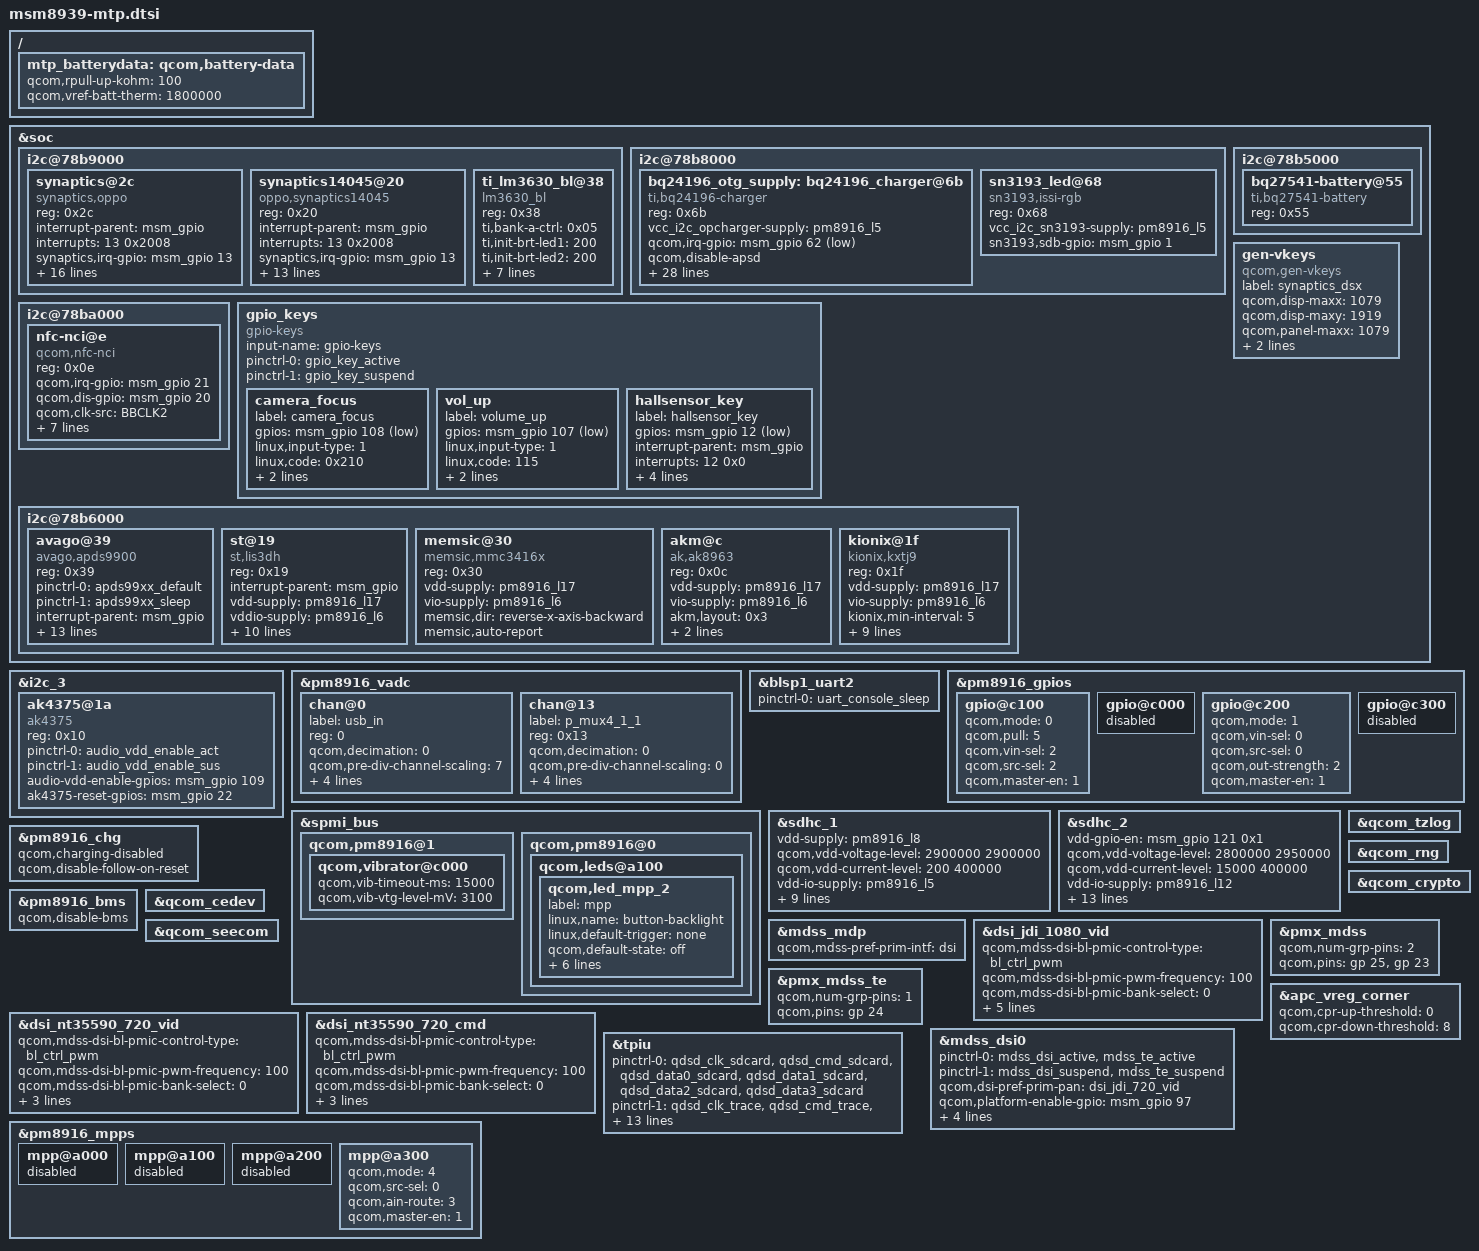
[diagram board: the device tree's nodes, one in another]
/* Copyright (c) 2014-2015, The Linux Foundation. All rights reserved.
 *
 * This program is free software; you can redistribute it and/or modify
 * it under the terms of the GNU General Public License version 2 and
 * only version 2 as published by the Free Software Foundation.
 *
 * This program is distributed in the hope that it will be useful,
 * but WITHOUT ANY WARRANTY; without even the implied warranty of
 * MERCHANTABILITY or FITNESS FOR A PARTICULAR PURPOSE.  See the
 * GNU General Public License for more details.
 */

#include "msm8939-pinctrl.dtsi"
#include "msm8939-camera-sensor-mtp.dtsi"

&soc {
	i2c@78b9000 { /* BLSP1 QUP5 */
	
		synaptics@2c {/*chenggang.li add for TP */
			compatible = "synaptics,oppo";
			reg = <0x2c>;
			interrupt-parent = <&msm_gpio>;
			interrupts = <13 0x2008>;
			synaptics,irq-gpio = <&msm_gpio 13 0x2008>;
			synaptics,id1-gpio = <&msm_gpio 51 0x00>;
			/*synaptics,id2-gpio = <&msm_gpio 66 0x00>;
			synaptics,id3-gpio = <&msm_gpio 119 0x00>;*/
			pinctrl-names = "default";
			pinctrl-0 = <&ts_id1_default   &ts_int_active>;
			synaptics,reset-gpio = <&msm_gpio 25 0x00>;
			synaptics,enable1v814045-gpio = <&msm_gpio 23 0x00>;
			vdd_2v8-supply = <&pm8916_l11>;
			vcc_i2c_1v8-supply = <&pm8916_l16>;
			synaptics,max-num-support = <10>;
			synaptics,max-x-point = <10>;
			synaptics,max-y-point = <1745>;
			synaptics,button-map= <200 200 1380>;//width-height-y.position
			synaptics,tx-rx-num = <28 18>;
			synaptics,display-coords = <720 1280>;
			synaptics,i2c-pull-up;
			synaptics,power-down;
			synaptics,disable-gpios;
			//synaptics,display-coords = <0 0 1079 1919>;
			synaptics,panel-coords = <0 0 1079 2084>;
		};
		
		synaptics14045@20 {/*tong.han add for TP */
			compatible = "oppo,synaptics14045";
			reg = <0x20>;
			interrupt-parent = <&msm_gpio>;
			interrupts = <13 0x2008>;
			synaptics,irq-gpio = <&msm_gpio 13 0x2008>;
			synaptics,id1-gpio = <&msm_gpio 51 0x00>;
			/*synaptics,id2-gpio = <&msm_gpio 66 0x00>;
			synaptics,id3-gpio = <&msm_gpio 119 0x00>;*/
			pinctrl-names = "default";
			pinctrl-0 = <&ts_id1_default   &ts_int_active>;
			//synaptics,reset-gpio = <&pm8916_gpios 2 0x00>;
			synaptics,max-num-support = <10>;
			synaptics,max-x-point = <10>;
			synaptics,max-y-point = <1745>;
			synaptics,button-map= <160 226 1400>;//width-height-y.position
			synaptics,tx-rx-num = <28 18>;
			synaptics,display-coords = <720 1280>;
			vdd_2v8-supply = <&pm8916_l11>;
			vcc_i2c_1v8-supply = <&pm8916_l16>;
			synaptics,i2c-pull-up;
			synaptics,power-down;
			synaptics,disable-gpios;
		};
		/* OPPO 2014-09-08 Xiaori.Yuan add begin for backlight lm3630 */
		ti_lm3630_bl@38 {
			compatible = "lm3630_bl";
			reg = <0x38>;
			ti,bank-a-ctrl = <0x05>;
			ti,init-brt-led1 = <200>;
			ti,init-brt-led2 = <200>;
			ti,max-brt-led1 = <255>;
			ti,max-brt-led2 = <255>;
			ti,pwm-active = <0>;
			ti,pwm-ctrl = <0>;
			ti,pwm-period = <255>;
			bl_i2c_1v8_enable_gpio = <&msm_gpio 23 0x00>;
			ti,bl-enable-gpio = <&msm_gpio 69 0>;
		};
		/* OPPO 2014-09-08 Xiaori.Yuan add end */
	};
	i2c@78b8000 { /* BLSP1 QUP4 =i2c4*/
		//Add bq24196_otg_supply for vbus_otg-supply by qiujianfeng
		bq24196_otg_supply: bq24196_charger@6b {
			status = "okay";
			compatible = "ti,bq24196-charger";
			reg = <0x6b>;

			vcc_i2c_opcharger-supply = <&pm8916_l5>;			/*Power source required to pull up i2c bus*/
			qcom,irq-gpio = <&msm_gpio 62 0x01>;					/*gpio STAT pin connects to.*/
			//qcom,fast_charger-gpio = <&msm_gpio 23 0x01>;			/*gpio fast_charger pin connects to.*/
			//qcom,usbphy_on-gpio = <&msm_gpio 38 0x01>;			/*gpio fast_charger pin connects to.*/
			//qcom,chg-valid-gpio= <&pm8941_gpios 0x02 0x01>;	/* */
			//qcom,charging-disabled;											/*This can then be overriden writing the the module parameter "charging_disabled"*/
			//qcom,chg-autonomous-mode;											/*it indicates that the charger is configured for autonomous operation*/
			qcom,disable-apsd;										/*APSD */
			qcom,bms-psy-name = "bms";									/*The main BMS device name */
			//qcom,iterm-disabled;
			qcom,charger-inhibit-disabled;							/* Charge Inhibit  */
			qcom,chg-vadc = <&pm8916_vadc>;							/* Corresponding VADC device's phandle.*/
			qcom,chg-adc_tm = <&pm8916_adc_tm>;						/* set recurring measurements and receive notification for batt_therm. */

			qcom,iterm-ma = <150>;									/*Charge termination current*/
			qcom,recharge-mv = <100>;									/* The minimum voltage drop for recharger*/
			qcom,fast-charger-project-sign= <0>;						/* fastcharger project sign*/	
			qcom,fastchg-current-max-ma = <1500>;						/*Maximum fast charging current.*/
			qcom,input-current-max-ma = <1500>;						/*Maximum input current.*/
			qcom,float-voltage-mv = <4320>;							/* from constant current charging to constant voltage chargeing for voltage threshold*/

			qcom,hot_bat_decidegc = <550>;							/* hot battery temperature in decidegC = 55*/
			qcom,temp_hot_vfloat_mv = <4100>;							/* hot battery temperature cutoff voltage =4.1V (45~55)*/
			qcom,temp_hot_fastchg_current_ma = <720>;					/* hot battery temperature fast current   =0.75A (45~55)*/

			qcom,warm_bat_decidegc = <450>;							/* Warm battery temperature in decidegC= 45*/
			qcom,temp_warm_vfloat_mv = <4320>;						/* warn battery temperature cutoff voltage =4.1V (5~45)*/
			qcom,temp_warm_fastchg_current_ma = <1500>;				/* warn battery temperature fast current   =0.75A (5~45)*/

			qcom,pre_normal_bat_decidegc = <200>;						/* pre_cool battery temperature in decidegC= 5*/	
			qcom,temp_pre_normal_vfloat_mv = <4320>;						/* warn battery temperature cutoff voltage =4.1V (5~45)*/
			qcom,temp_pre_normal_fastchg_current_ma = <1200>;			/* warn battery temperature fast current   =0.75A (5~45)*/

			qcom,pre_cool_bat_decidegc = <100>;						/* pre_cool battery temperature in decidegC= 5*/	
			qcom,temp_pre_cool_vfloat_mv = <4200>;					/* pre_cool battery temperature cutoff voltage =4.2V (0~5)*/
			qcom,temp_pre_cool_fastchg_current_ma = <500>;			/* pre_cool battery temperature fast current   =0.75A (0~5)*/

			qcom,cool_bat_decidegc = <0>;								/* cool battery temperature in decidegC= 0*/
			qcom,temp_cool_vfloat_mv = <4000>;						/* cool battery temperature cutoff voltage =4.0V (-10~0) */
			qcom,temp_cool_fastchg_current_ma = <300>;				/* cool battery temperature fast current   =0.25A(-10~0)*/

			qcom,cold_bat_decidegc = <100>;							/* cold battery temperature in decidegC= -10*/
			qcom,bat_present_decidegc = <200>;						/* battery decidegc temperature in decidegC= -20*/
			//qcom,non_standard_vfloat_mv = <4000>;
			//qcom,non_standard_fastchg_current_ma = <512>;

			//Modify regulator name by qiujianfeng
			regulator-name = "bq24196_otg_vreg";
		}; 		
                //#ifdef VENDOR_EDIT Jianfeng.Qiu@BSP.Driver, 2014-09-11, Add for breath led
                sn3193_led@68 {
                        status = "okay";
                        compatible = "sn3193,issi-rgb";
                        reg = <0x68>;
                        vcc_i2c_sn3193-supply = <&pm8916_l5>;			/*Power source required to pull up i2c bus*/
                        sn3193,sdb-gpio = <&msm_gpio 1 0x00>;
                };
                //#endif
	};
	i2c@78b5000 { /* BLSP1 QUP1 */
		bq27541-battery@55 {
			status = "okay";
			compatible = "ti,bq27541-battery";
			reg = <0x55>;

		};
	};
	gen-vkeys {
		compatible = "qcom,gen-vkeys";
		label = "synaptics_dsx";
		qcom,disp-maxx = <1079>;
		qcom,disp-maxy = <1919>;
		qcom,panel-maxx = <1079>;
		qcom,panel-maxy = <2084>;
		qcom,key-codes = <158 139 172 217>;
	};

	i2c@78ba000 { /* BLSP1 QUP6 */
		nfc-nci@e {
			compatible = "qcom,nfc-nci";
			reg = <0x0e>;
			qcom,irq-gpio = <&msm_gpio 21 0x00>;
			qcom,dis-gpio = <&msm_gpio 20 0x00>;
			qcom,clk-src = "BBCLK2";
			interrupt-parent = <&msm_gpio>;
			interrupts = <21 0>;
			interrupt-names = "nfc_irq";
			pinctrl-names = "nfc_active","nfc_suspend";
			pinctrl-0 = <&nfc_int_active &nfc_disable_active>;
			pinctrl-1 = <&nfc_int_suspend &nfc_disable_suspend>;
			qcom,clk-gpio = <&pm8916_gpios 2 0>;
			clocks = <&clock_rpm clk_bb_clk2_pin>;
			clock-names = "ref_clk";
		};
	};
	gpio_keys {
		compatible = "gpio-keys";
		input-name = "gpio-keys";
		pinctrl-names = "tlmm_gpio_key_active","tlmm_gpio_key_suspend";
		pinctrl-0 = <&gpio_key_active>;
		pinctrl-1 = <&gpio_key_suspend>;

		camera_focus {
			label = "camera_focus";
			gpios = <&msm_gpio 108 0x1>;
			linux,input-type = <1>;
			linux,code = <0x210>;
			gpio-key,wakeup;
			debounce-interval = <15>;
		};

		/*
		//#ifdef VENDOR_EDIT  
   		//deleted by zhengzhiyong@Multimedia.group (conflict with AUDIO_LDO_EN ) 2014-9-11  
		camera_snapshot {
			label = "camera_snapshot";
			gpios = <&msm_gpio 109 0x1>;
			linux,input-type = <1>;
			linux,code = <0x2fe>;
			gpio-key,wakeup;
			debounce-interval = <15>;
		};
		//#endif
		*/
		
		vol_up {
			label = "volume_up";
			gpios = <&msm_gpio 107 0x1>;
			linux,input-type = <1>;
			linux,code = <115>;
			gpio-key,wakeup;
			debounce-interval = <15>;
		};

		/* LiuPing@Phone.BSP.Sensor, 2014/11/07, add for hall */
		hallsensor_key {
			label = "hallsensor_key";
			gpios = <&msm_gpio 12 1>;
			interrupt-parent = <&msm_gpio>;
			interrupts = <12 0x0>;
			linux,input-type = <5>;
			linux,code = <0>;
			gpio-key,wakeup;
			debounce-interval = <150>;
		};

	};

	i2c@78b6000 { /* BLSP1 QUP2 */

	       /* LiuPing@Phone.BSP.Sensor, 2014/12/30, remove unused sensor. */
	       /* Gyroscope and accelerometer sensor combo */
	       /*
		mpu6050@68 { 
			compatible = "invn,mpu6050";
			reg = <0x68>;
			pinctrl-names = "mpu_default","mpu_sleep";
			pinctrl-0 = <&mpu6050_default>;
			pinctrl-1 = <&mpu6050_sleep>;
			interrupt-parent = <&msm_gpio>;
			interrupts = <115 0x2>;
			vdd-supply = <&pm8916_l17>;
			vlogic-supply = <&pm8916_l16>;
			vi2c-supply = <&pm8916_l6>;
			invn,gpio-int = <&msm_gpio 115 0x2>;
			invn,place = "Portrait Down Back Side";
		};*/

		avago@39 { /* Ambient light and proximity sensor */
			compatible = "avago,apds9900";
			reg = <0x39>;
			pinctrl-names = "default","sleep";
			pinctrl-0 = <&apds99xx_default>;
			pinctrl-1 = <&apds99xx_sleep>;
			interrupt-parent = <&msm_gpio>;
			interrupts = <9 0x2002>;
			vdd-supply = <&pm8916_l17>;
			vio-supply = <&pm8916_l6>;
			avago,irq-gpio = <&msm_gpio 9 0x2002>;
			avago,ps-threshold = <1023>;
			avago,ps-hysteresis-threshold = <1023>;
			avago,ps-pulse = <8>;
			avago,ps-pgain = <0>;
			avago,als-B = <223>;
			avago,als-C = <70>;
			avago,als-D = <142>;
			avago,als-gain = <80>;   // the true: lux = lux*als_gain/100.
			avago,ga-value = <48>;
		};

		/* LiuPing@Phone.BSP.Sensor, 2014/09/02, add for gsensor:lis3dh */
		st@19 { /* Accelerometer sensor */
			compatible = "st,lis3dh";
			reg = <0x19>;
			interrupt-parent = <&msm_gpio>;
			vdd-supply = <&pm8916_l17>;
			vddio-supply = <&pm8916_l6>;
			st,min-interval = <5>;
			st,init-interval = <200>;
			st,axis-map-x = <1>;
			st,axis-map-y = <0>;
			st,axis-map-z = <2>;
			st,g-range = <2>;
			st,gpio-int1 = <&msm_gpio 34 0x2002>;
			st,negate-x;
			st,negate-y;			
			st,negate-z;
		};			

		/* LiuPing@Phone.BSP.Sensor, 2014/09/04, add for msensor:mmc3416x */
		memsic@30 { /* Magnetic field sensor */
		compatible = "memsic,mmc3416x";
		reg = <0x30>;
		vdd-supply = <&pm8916_l17>;
		vio-supply = <&pm8916_l6>;
		memsic,dir = "reverse-x-axis-backward";
		memsic,auto-report;
		};		

		/* LiuPing@Phone.BSP.Sensor, 2014/10/30, add for msensor:akm8963 */
		akm@c {
			compatible = "ak,ak8963";
			reg = <0x0c>;
			/* pinctrl-names = "ak8963_default", "ak8963_sleep";
			pinctrl-0 = <&ak8963_default>;
			pinctrl-1 = <&ak8963_sleep>;
			interrupt-parent = <&msm_gpio>;
			interrupts = <69 0x2>; */
			vdd-supply = <&pm8916_l17>;
			vio-supply = <&pm8916_l6>;
			akm,layout = <0x3>;
			akm,gpio_rstn = <&msm_gpio 106 0x0>;
			akm,auto-report;
		};
		/* LiuPing@Phone.BSP.Sensor, 2014/10/30, add for gsensor:kx023 */
		kionix@1f { 
			compatible = "kionix,kxtj9";
			reg = <0x1f>;
			//interrupt-parent = <&msm_gpio>;
			//interrupts = <34 0x2>;
			vdd-supply = <&pm8916_l17>;
			vio-supply = <&pm8916_l6>;
			kionix,min-interval = <5>;
			kionix,init-interval = <200>;
			kionix,axis-map-x = <1>;
			kionix,axis-map-y = <0>;
			kionix,axis-map-z = <2>;
			kionix,g-range = <2>;
			kionix,negate-x;
			kionix,negate-y;
			kionix,negate-z;
			kionix,res-12bit; 
		};

	};

};
/*OPPO 2014-08-20 zhzhyon Add for ak4375*/
&i2c_3 {
		  ak4375@1a {
			compatible = "ak4375";
			reg = <0x10>;
			pinctrl-names = "cdc_audio_enable_act",
				  "cdc_audio_enable_sus";
			pinctrl-0 = <&audio_vdd_enable_act>;
		  pinctrl-1 = <&audio_vdd_enable_sus>;
			audio-vdd-enable-gpios = <&msm_gpio 109 0x00>;	
			/*OPPO 2014-09-23 zhzhyon Add for ak4375 resource*/
			ak4375-reset-gpios = <&msm_gpio 22 0x00>;
			/*OPPO 2014-09-23 zhzhyon Add end*/
		};		
	};
/*OPPO 2014-08-20 zhzhyon Add end*/


/*dengnw  add for  adc 2014-07-22 start*/
&pm8916_vadc {
	chan@0 {
		label = "usb_in";
		reg = <0>;
		qcom,decimation = <0>;
		qcom,pre-div-channel-scaling = <7>;
		qcom,calibration-type = "absolute";
		qcom,scale-function = <0>;
		qcom,hw-settle-time = <0>;
		qcom,fast-avg-setup = <0>;
	};
	chan@13 {
		label = "p_mux4_1_1";
		reg = <0x13>;
		qcom,decimation = <0>;
		qcom,pre-div-channel-scaling = <0>;
		qcom,calibration-type = "absolute";
		qcom,scale-function = <0>;
		qcom,hw-settle-time = <2>;
		qcom,fast-avg-setup = <0>;
	};
};
/*dengnw  add for  adc 2014-07-22 end*/
&blsp1_uart2 {
	status = "ok";
	pinctrl-names = "default";
	pinctrl-0 = <&uart_console_sleep>;
};

&pm8916_gpios {
	gpio@c100 { /* GPIO 2 */
		/* NFC_CLK_REQ */
		qcom,mode = <0>; /* QPNP_PIN_MODE_DIG_IN */
		qcom,pull = <5>; /* QPNP_PIN_PULL_NO */
		qcom,vin-sel = <2>; /* QPNP_PIN_VIN2 */
		qcom,src-sel = <2>; /* QPNP_PIN_SEL_FUNC_1 */
		qcom,master-en = <1>;
	};
};
&spmi_bus {
	qcom,pm8916@1 {
		qcom,vibrator@c000 {
			status = "okay";
			qcom,vib-timeout-ms = <15000>;
			qcom,vib-vtg-level-mV = <3100>;
		};
	};

	qcom,pm8916@0 {
		qcom,leds@a100 {
			status = "okay";
			qcom,led_mpp_2 {
				label = "mpp";
				linux,name = "button-backlight";
				linux,default-trigger = "none";
				qcom,default-state = "off";
				qcom,max-current = <40>;
				qcom,current-setting = <5>;
				qcom,id = <6>;
				qcom,mode = "manual";
				qcom,source-sel = <1>;
				qcom,mode-ctrl = <0x60>;
			};
		};
	};
};

&sdhc_1 {
	vdd-supply = <&pm8916_l8>;
	qcom,vdd-voltage-level = <2900000 2900000>;
	qcom,vdd-current-level = <200 400000>;

	vdd-io-supply = <&pm8916_l5>;
	qcom,vdd-io-always-on;
	qcom,vdd-io-lpm-sup;
	qcom,vdd-io-voltage-level = <1800000 1800000>;
	qcom,vdd-io-current-level = <200 60000>;

	pinctrl-names = "active", "sleep";
	pinctrl-0 = <&sdc1_clk_on &sdc1_cmd_on &sdc1_data_on>;
	pinctrl-1 = <&sdc1_clk_off &sdc1_cmd_off &sdc1_data_off>;

	qcom,nonremovable;

	status = "ok";
};

&sdhc_2 {
//#ifndef VENDOR_EDIT //Jianfeng.Qiu@BSP.Driver, 2014-09-13, Modify for tf card vdd supply change
	//vdd-supply = <&pm8916_l11>;
//#else /* VENDOR_EDIT */
    vdd-gpio-en = <&msm_gpio 121 0x1>;
//#endif /* VENDOR_EDIT */
	qcom,vdd-voltage-level = <2800000 2950000>;
	qcom,vdd-current-level = <15000 400000>;

	vdd-io-supply = <&pm8916_l12>;
	qcom,vdd-io-voltage-level = <1800000 2950000>;
	qcom,vdd-io-current-level = <200 50000>;

	//#ifndef VENDOR_EDIT //Jianfeng.Qiu@BSP.Drv, 2014-8-13, Modify for delete card hotplug
	//pinctrl-names = "active", "sleep";
	//pinctrl-0 = <&sdc2_clk_on &sdc2_cmd_on &sdc2_data_on &sdc2_cd_on>;
	//pinctrl-1 = <&sdc2_clk_off &sdc2_cmd_off &sdc2_data_off &sdc2_cd_off>;
	//#else
	pinctrl-names = "default", "active", "sleep";
	pinctrl-0 = <&sdc2_cd_on &sim1_cd_on &sim2_cd_on>;
	pinctrl-1 = <&sdc2_clk_on &sdc2_cmd_on &sdc2_data_on &sdc2_cd_on>;
	pinctrl-2 = <&sdc2_clk_off &sdc2_cmd_off &sdc2_data_off &sdc2_cd_off>;
	//#endif
	
	#address-cells = <0>;
	interrupt-parent = <&sdhc_2>;
	
	//#ifndef VENDOR_EDIT //Jianfeng.Qiu@BSP.Drv, 2014-8-13, Modify for delete card hotplug
	interrupts = <0 1 2>;
	#interrupt-cells = <1>;
	interrupt-map-mask = <0xffffffff>;
	interrupt-map = <0 &intc 0 125 0
			1 &intc 0 221 0
			2 &msm_gpio 38 0>;
	interrupt-names = "hc_irq", "pwr_irq", "status_irq";
	//#ifdef VENDOR_EDIT //yixue.ge modify for 14045 tcard hotplug
	//cd-gpios = <&msm_gpio 38 0x1>;
	//#else
	cd-gpios = <&msm_gpio 38 0x0>;
	//#endif
	//#else
	/*	
	interrupts = <0 1>;
	#interrupt-cells = <1>;
	interrupt-map-mask = <0xffffffff>;
	interrupt-map = <0 &intc 0 125 0
			1 &intc 0 221 0>;
	interrupt-names = "hc_irq", "pwr_irq";
	*/
	//#endif
	status = "ok";
};

&pm8916_chg {
	status = "ok";
	qcom,charging-disabled;
	/*dengnw@bsp.drv  add for  adc 2014-07-22 end*/
	qcom,disable-follow-on-reset;
};

/ {
	mtp_batterydata: qcom,battery-data {
		qcom,rpull-up-kohm = <100>;
		qcom,vref-batt-therm = <1800000>;

		#include "batterydata-palladium.dtsi"
	};
};

&pm8916_bms {
	status = "ok";
	/*dengnw@bsp.drv  add for  adc 2014-07-22 end*/
//	qcom,battery-data = <&mtp_batterydata>;
	qcom,disable-bms;
};

&qcom_tzlog {
	status = "okay";
};

&qcom_rng {
	status = "okay";
};

&qcom_crypto {
	status = "okay";
};

&qcom_cedev {
	status = "okay";
};

&qcom_seecom {
	status = "okay";
};

#include "dsi-panel-jdi-1080p-video.dtsi"
#include "dsi-panel-nt35590-720p-video.dtsi"
#include "dsi-panel-nt35590-720p-cmd.dtsi"
/*Xiaori.Yuan add for lcd*/
#include "dsi-panel-jdi-720p-video.dtsi"
#include "dsi-panel-oppo14045-720p-cmd.dtsi"
#include "dsi-panel-oppo14017-720p-cmd.dtsi"
#include "dsi-panel-oppo14017synaptics-720p-video.dtsi"
/*Xiaori.Yuan add end*/
&mdss_mdp {
	qcom,mdss-pref-prim-intf = "dsi";
};

&dsi_jdi_1080_vid {
	qcom,mdss-dsi-bl-pmic-control-type = "bl_ctrl_pwm";
	qcom,mdss-dsi-bl-pmic-pwm-frequency = <100>;
	qcom,mdss-dsi-bl-pmic-bank-select = <0>;
	qcom,mdss-dsi-pwm-gpio = <&pm8916_mpps 4 0>;
	qcom,cont-splash-enabled;
	qcom,mdss-dsi-pan-enable-dynamic-fps;
	qcom,mdss-dsi-pan-fps-update = "dfps_immediate_porch_mode";
};

&dsi_nt35590_720_vid {
	qcom,mdss-dsi-bl-pmic-control-type = "bl_ctrl_pwm";
	qcom,mdss-dsi-bl-pmic-pwm-frequency = <100>;
	qcom,mdss-dsi-bl-pmic-bank-select = <0>;
	qcom,mdss-dsi-pwm-gpio = <&pm8916_mpps 4 0>;
	qcom,cont-splash-enabled;
	qcom,esd-check-enabled;
};

&dsi_nt35590_720_cmd {
	qcom,mdss-dsi-bl-pmic-control-type = "bl_ctrl_pwm";
	qcom,mdss-dsi-bl-pmic-pwm-frequency = <100>;
	qcom,mdss-dsi-bl-pmic-bank-select = <0>;
	qcom,mdss-dsi-pwm-gpio = <&pm8916_mpps 4 0>;
	qcom,cont-splash-enabled;
	qcom,esd-check-enabled;
};

&pmx_mdss {
	qcom,num-grp-pins = <2>;
	/*yxr delete*/
	/*qcom,pins = <&gp 97>, <&gp 25>, <&gp 98>;*/
	qcom,pins = <&gp 25>, <&gp 23>;
};

&pmx_mdss_te {
	qcom,num-grp-pins = <1>;
	qcom,pins = <&gp 24>;
};

/*OPPO Xiaori.Yuan modified for lcd*/
#include "dsi-panel-samsung_ams520bq04_s6e3fa2x01_1080p_cmd.dtsi"
&mdss_dsi0 {
	pinctrl-names = "mdss_default", "mdss_sleep";
	pinctrl-0 = <&mdss_dsi_active &mdss_te_active>;
	pinctrl-1 = <&mdss_dsi_suspend &mdss_te_suspend>;
	qcom,dsi-pref-prim-pan = <&dsi_jdi_720_vid>;

	qcom,platform-enable-gpio = <&msm_gpio 97 0>;
	qcom,platform-enn-enable-gpio = <&msm_gpio 23 0>;
	qcom,platform-reset-gpio = <&msm_gpio 25 0>;
	/*qcom,platform-te-gpio = <&msm_gpio 24 0>;
	qcom,platform-bklight-en-gpio = <&msm_gpio 98 0>;*/
	/*Xiaori.Yuan add for ESD test*/
	vdddc_3v3-supply = <&pm8916_l11>;
	vddf_2v5-supply = <&pm8916_l16>;
	/*add end*/
};
/*OPPO Xiaori.Yuan modified end*/

&pm8916_mpps {
	mpp@a000 { /* MPP 1 */
		/* VDD_PX */
		status = "disabled";
	};

	mpp@a100 { /* MPP 2 */
		/* HR LED */
		status = "disabled";
	};

	mpp@a200 { /* MPP 3 */
		/* VREF DAC */
		status = "disabled";
	};

	/*dengnw add for MPP4 to adc 2014-07-22 start*/
/*
	mpp@a300 { 
		// Backlight PWM //
		qcom,mode = <1>;		// Digital output //
		qcom,invert = <0>;		//Disable invert //
		qcom,src-sel = <4>;		//DTEST1 //
		qcom,vin-sel = <0>;		// VPH_PWR //
		qcom,master-en = <1>;		// Enable MPP //
	};
*/
	mpp@a300 { /* MPP 4 */
		// adc   //
		qcom,mode = <4>; // QPNP_PIN_MODE_AIN 
		qcom,src-sel = <0>; // QPNP_PIN_SEL_FUNC_CONSTANT 
		qcom,ain-route = <3>; // QPNP_PIN_AIN_AMUX_CH8 
		qcom,master-en = <1>; // Enable features 
	}; 
	/*dengnw add for MPP4 to adc 2014-07-22 end*/
};

&pm8916_gpios {
	gpio@c000 { /* GPIO 1 */
		/* Battery UICC Alarm */
		status = "disabled";
	};

	gpio@c100 { /* GPIO 2 */
		/* NFC_CLK_REQ */
		qcom,mode = <0>; /* QPNP_PIN_MODE_DIG_IN */
		qcom,pull = <5>; /* QPNP_PIN_PULL_NO */
		qcom,vin-sel = <2>; /* QPNP_PIN_VIN2 */
		qcom,src-sel = <2>; /* QPNP_PIN_SEL_FUNC_1 */
		qcom,master-en = <1>;
	};

	gpio@c200 { /* GPIO 3 */
		/* External regulator control for WTR */
        /* xianglie.liu 2014-09-03 modify for camera vana-en pin */
		qcom,mode = <1>; /* QPNP_PIN_MODE_DIG_OUT */
		qcom,vin-sel = <0>; /* VPH_PWR */
		qcom,src-sel = <0>; /* QPNP_PIN_SEL_FUNC_CONSTANT */
		qcom,out-strength = <2>; /* QPNP_PIN_OUT_STRENGTH_MED */
		qcom,master-en = <1>;
		status = "ok";
       /* xianglie.liu modify end */ 
	};

	gpio@c300 { /* GPIO 4 */
		/* External regulator control for APC */
		status = "disabled";
	};
};

/* CoreSight */
&tpiu {
	pinctrl-names = "sdcard", "trace", "swduart",
			"swdtrc", "jtag", "spmi";
	/* NIDnT */
	pinctrl-0 = <&qdsd_clk_sdcard &qdsd_cmd_sdcard
		     &qdsd_data0_sdcard &qdsd_data1_sdcard
		     &qdsd_data2_sdcard &qdsd_data3_sdcard>;
	pinctrl-1 = <&qdsd_clk_trace &qdsd_cmd_trace
		     &qdsd_data0_trace &qdsd_data1_trace
		     &qdsd_data2_trace &qdsd_data3_trace>;
	pinctrl-2 = <&qdsd_cmd_swduart &qdsd_data0_swduart
		     &qdsd_data1_swduart &qdsd_data2_swduart
		     &qdsd_data3_swduart>;
	pinctrl-3 = <&qdsd_clk_swdtrc &qdsd_cmd_swdtrc
		     &qdsd_data0_swdtrc &qdsd_data1_swdtrc
		     &qdsd_data2_swdtrc &qdsd_data3_swdtrc>;
	pinctrl-4 = <&qdsd_cmd_jtag &qdsd_data0_jtag
		     &qdsd_data1_jtag &qdsd_data2_jtag
		     &qdsd_data3_jtag>;
	pinctrl-5 = <&qdsd_clk_spmi &qdsd_cmd_spmi
		     &qdsd_data0_spmi &qdsd_data3_spmi>;
};

&apc_vreg_corner {
		qcom,cpr-up-threshold = <0>;
		qcom,cpr-down-threshold = <8>;
};
